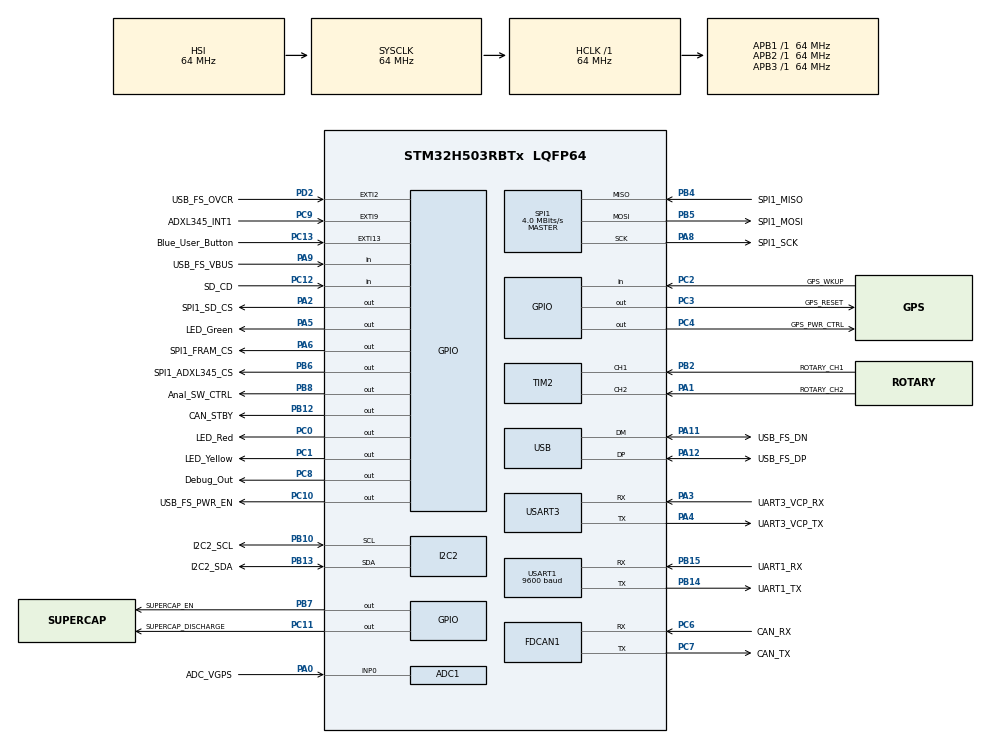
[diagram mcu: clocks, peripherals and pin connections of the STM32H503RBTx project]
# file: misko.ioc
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ADC1.Channel-1\#ChannelRegularConversion=ADC_CHANNEL_0
ADC1.Channel-2\#ChannelRegularConversion=ADC_CHANNEL_VBAT
ADC1.Channel-3\#ChannelRegularConversion=ADC_CHANNEL_TEMPSENSOR
ADC1.Channel-4\#ChannelRegularConversion=ADC_CHANNEL_VREFINT
ADC1.DMAContinuousRequests=ENABLE
ADC1.EnableAnalogWatchDog2=false
ADC1.ExternalTrigConv=ADC_EXTERNALTRIG_T1_TRGO
ADC1.MonitoredBy-1\#ChannelRegularConversion=__NULL
ADC1.MonitoredBy-2\#ChannelRegularConversion=__NULL
ADC1.MonitoredBy-3\#ChannelRegularConversion=__NULL
ADC1.MonitoredBy-4\#ChannelRegularConversion=__NULL
ADC1.NbrOfConversion=4
ADC1.NbrOfConversionFlag=1
ADC1.Offset-1\#ChannelRegularConversion=0
ADC1.Offset-2\#ChannelRegularConversion=0
ADC1.Offset-3\#ChannelRegularConversion=0
ADC1.Offset-4\#ChannelRegularConversion=0
ADC1.OffsetNumber-1\#ChannelRegularConversion=ADC_OFFSET_NONE
ADC1.OffsetNumber-2\#ChannelRegularConversion=ADC_OFFSET_NONE
ADC1.OffsetNumber-3\#ChannelRegularConversion=ADC_OFFSET_NONE
ADC1.OffsetNumber-4\#ChannelRegularConversion=ADC_OFFSET_NONE
ADC1.Overrun=ADC_OVR_DATA_OVERWRITTEN
ADC1.Rank-1\#ChannelRegularConversion=1
ADC1.Rank-2\#ChannelRegularConversion=2
ADC1.Rank-3\#ChannelRegularConversion=3
ADC1.Rank-4\#ChannelRegularConversion=4
ADC1.Resolution=ADC_RESOLUTION_12B
ADC1.SamplingTime-1\#ChannelRegularConversion=ADC_SAMPLETIME_640CYCLES_5
ADC1.SamplingTime-2\#ChannelRegularConversion=ADC_SAMPLETIME_640CYCLES_5
ADC1.SamplingTime-3\#ChannelRegularConversion=ADC_SAMPLETIME_640CYCLES_5
ADC1.SamplingTime-4\#ChannelRegularConversion=ADC_SAMPLETIME_640CYCLES_5
ADC1.master=1
BOOTPATH.BootPathName=LEGACY
BOOTPATH.UserSelectedBootPath=LEGACY
CORTEX_M33_NS.AccessPermission-Cortex_Memory_Protection_Unit_Region0_Settings=MPU_REGION_ALL_RO
CORTEX_M33_NS.BaseAddress-Cortex_Memory_Protection_Unit_Region0_Settings=0x08FFF810
CORTEX_M33_NS.DisableExec-Cortex_Memory_Protection_Unit_Region0_Settings=MPU_INSTRUCTION_ACCESS_DISABLE
CORTEX_M33_NS.Enable-Cortex_Memory_Protection_Unit_Region0_Settings=MPU_REGION_ENABLE
CORTEX_M33_NS.LimitAddress-Cortex_Memory_Protection_Unit_Region0_Settings=0x08FFF819
CORTEX_M33_NS.MPU_Control=MPU_HFNMI_PRIVDEF
FDCAN1.CalculateBaudRateNominal=166666
FDCAN1.CalculateTimeBitNominal=6000
FDCAN1.CalculateTimeQuantumNominal=2000.0
FDCAN1.ClockDivider=FDCAN_CLOCK_DIV1
GPDMA1.CIRCULARMODE_GPDMACH1=ENABLE
GPDMA1.CIRCULARMODE_GPDMACH3=ENABLE
GPDMA1.CIRCULARMODE_GPDMACH5=ENABLE
GPDMA1.DESTDATAWIDTH_GPDMACH5=DMA_DEST_DATAWIDTH_WORD
GPDMA1.DESTINC_GPDMACH1=DMA_DINC_INCREMENTED
GPDMA1.DESTINC_GPDMACH3=DMA_DINC_INCREMENTED
GPDMA1.DESTINC_GPDMACH5=DMA_DINC_INCREMENTED
GPDMA1.DIRECTION_GPDMACH0=DMA_MEMORY_TO_PERIPH
GPDMA1.IPHANDLE_GPDMACH0-SIMPLEREQUEST_GPDMACH0=__NULL
GPDMA1.IPHANDLE_GPDMACH1-SIMPLEREQUEST_GPDMACH1=__NULL
GPDMA1.IPHANDLE_GPDMACH3-SIMPLEREQUEST_GPDMACH3=__NULL
GPDMA1.IPHANDLE_GPDMACH5-SIMPLEREQUEST_GPDMACH5=__NULL
GPDMA1.LINKALLOCATEDPORT_CIRCULAR_GPDMACH1=DMA_LINK_ALLOCATED_PORT1
GPDMA1.LINKALLOCATEDPORT_GPDMACH7=DMA_LINK_ALLOCATED_PORT1
GPDMA1.PRIORITY_LL_GPDMACH6=DMA_LOW_PRIORITY_HIGH_WEIGHT
GPDMA1.PRIORITY_LL_GPDMACH7=DMA_LOW_PRIORITY_HIGH_WEIGHT
GPDMA1.RECAP_GPDMACH0=USART3_TX
GPDMA1.RECAP_GPDMACH1=USART3_RX
GPDMA1.RECAP_GPDMACH3=USART1_RX
GPDMA1.RECAP_GPDMACH5=ADC1
GPDMA1.REQUEST_GPDMACH0=GPDMA1_REQUEST_USART3_TX
GPDMA1.REQUEST_GPDMACH1=GPDMA1_REQUEST_USART3_RX
GPDMA1.REQUEST_GPDMACH3=GPDMA1_REQUEST_USART1_RX
GPDMA1.REQUEST_GPDMACH5=GPDMA1_REQUEST_ADC1
GPDMA1.SRCDATAWIDTH_GPDMACH5=DMA_SRC_DATAWIDTH_WORD
GPDMA1.SRCINC_GPDMACH0=DMA_SINC_INCREMENTED
GPDMA1.TRANSFERALLOCATEDPORTDEST_GPDMACH1=DMA_DEST_ALLOCATED_PORT1
GPDMA1.TRANSFERALLOCATEDPORTSRC_GPDMACH1=DMA_SRC_ALLOCATED_PORT1
GPDMA1.TRIGGERPOLARITY_GPDMACH5=DMA_TRIG_POLARITY_MASKED
GPDMA2.DESTINC_GPDMACH1=DMA_DINC_INCREMENTED
GPDMA2.IPHANDLE_GPDMACH0-SIMPLEREQUEST_GPDMACH0=__NULL
GPDMA2.IPHANDLE_GPDMACH1-SIMPLEREQUEST_GPDMACH1=__NULL
GPDMA2.REQUEST_GPDMACH0=GPDMA2_REQUEST_I2C2_TX
GPDMA2.REQUEST_GPDMACH1=GPDMA2_REQUEST_I2C2_RX
GPDMA2.SRCINC_GPDMACH0=DMA_SINC_INCREMENTED
I2C2.Timing=0x10707DBC
Linkedlist.MDMA_Channel0.GP_SW.0.BlkHWRequest=DMA_BREQ_SINGLE_BURST
Linkedlist.MDMA_Channel0.GP_SW.0.DataHandling=NONE
Linkedlist.MDMA_Channel0.GP_SW.0.DataSize=0
Linkedlist.MDMA_Channel0.GP_SW.0.DestBurstLength=1
Linkedlist.MDMA_Channel0.GP_SW.0.DestDataWidth=DMA_DEST_DATAWIDTH_BYTE
Linkedlist.MDMA_Channel0.GP_SW.0.DestInc=DMA_DINC_FIXED
Linkedlist.MDMA_Channel0.GP_SW.0.Direction=DMA_MEMORY_TO_PERIPH
Linkedlist.MDMA_Channel0.GP_SW.0.DstAddress=0
Linkedlist.MDMA_Channel0.GP_SW.0.Instance=MDMA_Channel0
Linkedlist.MDMA_Channel0.GP_SW.0.LL_MASTERDMA=GPDMA1
Linkedlist.MDMA_Channel0.GP_SW.0.LL_NAME=Queue_tx
Linkedlist.MDMA_Channel0.GP_SW.0.LL_TYPE=LINEAR
Linkedlist.MDMA_Channel0.GP_SW.0.Mode=DMA_NORMAL
Linkedlist.MDMA_Channel0.GP_SW.0.NODE_NAME=Node_tx
Linkedlist.MDMA_Channel0.GP_SW.0.Requestforcodegen=GPDMA1_REQUEST_SPI1_TX
Linkedlist.MDMA_Channel0.GP_SW.0.SrcAddress=0
Linkedlist.MDMA_Channel0.GP_SW.0.SrcBurstLength=1
Linkedlist.MDMA_Channel0.GP_SW.0.SrcDataWidth=DMA_SRC_DATAWIDTH_BYTE
Linkedlist.MDMA_Channel0.GP_SW.0.SrcInc=DMA_SINC_INCREMENTED
Linkedlist.MDMA_Channel0.GP_SW.0.TransferAllocatedPortSrc=DMA_SRC_ALLOCATED_PORT1
Linkedlist.MDMA_Channel0.GP_SW.0.TransferEventMode=DMA_TCEM_BLOCK_TRANSFER
Linkedlist.MDMA_Channel0.GP_SW.0.TriggerPolarity=DMA_TRIG_POLARITY_MASKED
Linkedlist.MDMA_Channel0.Request0=GP_SW
Linkedlist.MDMA_Channel0.RequestsNb=1
Linkedlist.MDMA_Channel1.GP_SW.0.BlkHWRequest=DMA_BREQ_SINGLE_BURST
Linkedlist.MDMA_Channel1.GP_SW.0.DataHandling=NONE
Linkedlist.MDMA_Channel1.GP_SW.0.DataSize=0
Linkedlist.MDMA_Channel1.GP_SW.0.DestBurstLength=1
Linkedlist.MDMA_Channel1.GP_SW.0.DestDataWidth=DMA_DEST_DATAWIDTH_BYTE
Linkedlist.MDMA_Channel1.GP_SW.0.DestInc=DMA_DINC_INCREMENTED
Linkedlist.MDMA_Channel1.GP_SW.0.Direction=DMA_PERIPH_TO_MEMORY
Linkedlist.MDMA_Channel1.GP_SW.0.DstAddress=0
Linkedlist.MDMA_Channel1.GP_SW.0.Instance=MDMA_Channel1
Linkedlist.MDMA_Channel1.GP_SW.0.LL_MASTERDMA=GPDMA1
Linkedlist.MDMA_Channel1.GP_SW.0.LL_NAME=Queue_rx
Linkedlist.MDMA_Channel1.GP_SW.0.LL_TYPE=LINEAR
Linkedlist.MDMA_Channel1.GP_SW.0.Mode=DMA_NORMAL
Linkedlist.MDMA_Channel1.GP_SW.0.NODE_NAME=Node_rx
Linkedlist.MDMA_Channel1.GP_SW.0.Requestforcodegen=GPDMA1_REQUEST_SPI1_RX
Linkedlist.MDMA_Channel1.GP_SW.0.SrcAddress=0
Linkedlist.MDMA_Channel1.GP_SW.0.SrcBurstLength=1
Linkedlist.MDMA_Channel1.GP_SW.0.SrcDataWidth=DMA_SRC_DATAWIDTH_BYTE
Linkedlist.MDMA_Channel1.GP_SW.0.SrcInc=DMA_SINC_FIXED
Linkedlist.MDMA_Channel1.GP_SW.0.TransferAllocatedPortSrc=DMA_SRC_ALLOCATED_PORT0
Linkedlist.MDMA_Channel1.GP_SW.0.TransferEventMode=DMA_TCEM_BLOCK_TRANSFER
Linkedlist.MDMA_Channel1.GP_SW.0.TriggerPolarity=DMA_TRIG_POLARITY_MASKED
Linkedlist.MDMA_Channel1.Request0=GP_SW
Linkedlist.MDMA_Channel1.RequestsNb=1
Linkedlist.RequestSet0=MDMA_Channel0
Linkedlist.RequestSet1=MDMA_Channel1
Linkedlist.RequestSetsNb=2
Mcu.Family=STM32H5
Mcu.Name=STM32H503RBTx
Mcu.Package=LQFP64
NVIC.ADC1_IRQn=true\:0\:0\:false\:false\:true\:true\:true\:true
NVIC.EXTI13_IRQn=true\:4\:0\:true\:false\:true\:true\:true\:true
NVIC.EXTI2_IRQn=true\:0\:0\:false\:false\:true\:true\:true\:true
NVIC.EXTI9_IRQn=true\:1\:0\:true\:false\:true\:true\:true\:true
NVIC.FDCAN1_IT0_IRQn=true\:0\:0\:false\:false\:true\:true\:true\:true
NVIC.FDCAN1_IT1_IRQn=true\:0\:0\:false\:false\:true\:true\:true\:true
NVIC.GPDMA1_Channel0_IRQn=true\:0\:0\:false\:false\:true\:true\:true\:true
NVIC.GPDMA1_Channel1_IRQn=true\:0\:0\:false\:false\:true\:true\:true\:true
NVIC.GPDMA1_Channel3_IRQn=true\:0\:0\:true\:false\:true\:false\:true\:true
NVIC.GPDMA1_Channel5_IRQn=true\:0\:0\:false\:false\:true\:false\:true\:true
NVIC.GPDMA1_Channel6_IRQn=true\:0\:0\:false\:false\:true\:true\:true\:true
NVIC.GPDMA1_Channel7_IRQn=true\:0\:0\:false\:false\:true\:true\:true\:true
NVIC.GPDMA2_Channel0_IRQn=true\:0\:0\:false\:false\:true\:false\:true\:true
NVIC.GPDMA2_Channel1_IRQn=true\:0\:0\:false\:false\:true\:false\:true\:true
NVIC.PriorityGroup=NVIC_PRIORITYGROUP_3
NVIC.SPI1_IRQn=true\:0\:0\:false\:false\:true\:true\:true\:true
NVIC.TIM1_CC_IRQn=true\:0\:0\:false\:false\:true\:true\:true\:true
NVIC.TIM2_IRQn=true\:0\:0\:false\:false\:true\:true\:true\:true
NVIC.USART1_IRQn=true\:2\:0\:true\:false\:true\:true\:true\:true
NVIC.USART3_IRQn=true\:3\:0\:true\:false\:true\:true\:true\:true
PA0.GPIO_Label=ADC_VGPS
PA0.Signal=ADCx_INP0
PA1.GPIO_Label=ROTARY_CH2
PA1.Signal=S_TIM2_CH2
PA11.GPIO_Label=USB_FS_DN
PA11.Mode=Device
PA11.Signal=USB_DM
PA12.GPIO_Label=USB_FS_DP
PA12.Mode=Device
PA12.Signal=USB_DP
PA13(JTMS/SWDIO).GPIO_Label=SWDIO
PA13(JTMS/SWDIO).Mode=JTAG_4_pins
PA13(JTMS/SWDIO).Signal=DEBUG_JTMS-SWDIO
PA14(JTCK/SWCLK).GPIO_Label=SWCLK
PA14(JTCK/SWCLK).Mode=JTAG_4_pins
PA14(JTCK/SWCLK).Signal=DEBUG_JTCK-SWCLK
PA15(JTDI).GPIO_Label=JTDI
PA15(JTDI).Mode=JTAG_4_pins
PA15(JTDI).Signal=DEBUG_JTDI
PA2.GPIO_Label=SPI1_SD_CS
PA2.GPIO_PuPd=GPIO_PULLUP
PA2.PinState=GPIO_PIN_SET
PA2.Signal=GPIO_Output
PA3.GPIO_Label=UART3_VCP_RX
PA3.GPIO_PuPd=GPIO_PULLUP
PA3.Mode=Asynchronous
PA3.Signal=USART3_RX
PA4.GPIO_Label=UART3_VCP_TX
PA4.GPIO_PuPd=GPIO_PULLUP
PA4.Mode=Asynchronous
PA4.Signal=USART3_TX
PA5.GPIO_Label=LED_Green
PA5.PinState=GPIO_PIN_RESET
PA5.Signal=GPIO_Output
PA6.GPIO_Label=SPI1_FRAM_CS
PA6.GPIO_PuPd=GPIO_PULLUP
PA6.PinState=GPIO_PIN_SET
PA6.Signal=GPIO_Output
PA8.GPIO_Label=SPI1_SCK
PA8.GPIO_PuPd=GPIO_PULLUP
PA8.Mode=Full_Duplex_Master
PA8.Signal=SPI1_SCK
PA9.GPIO_Label=USB_FS_VBUS
PA9.Signal=GPIO_Input
PB10.GPIO_Label=I2C2_SCL
PB10.GPIO_Pu=GPIO_PULLUP
PB10.Mode=I2C
PB10.Signal=I2C2_SCL
PB12.GPIO_Label=CAN_STBY
PB12.Signal=GPIO_Output
PB13.GPIO_Label=I2C2_SDA
PB13.GPIO_Pu=GPIO_PULLUP
PB13.Mode=I2C
PB13.Signal=I2C2_SDA
PB14.GPIO_Label=UART1_TX
PB14.GPIO_PuPd=GPIO_PULLUP
PB14.Mode=Asynchronous
PB14.Signal=USART1_TX
PB15.GPIO_Label=UART1_RX
PB15.GPIO_PuPd=GPIO_PULLUP
PB15.Mode=Asynchronous
PB15.Signal=USART1_RX
PB2.GPIO_Label=ROTARY_CH1
PB2.Signal=S_TIM2_CH1
PB3(JTDO/TRACESWO).GPIO_Label=SWO
PB3(JTDO/TRACESWO).Mode=JTAG_4_pins
PB3(JTDO/TRACESWO).Signal=DEBUG_JTDO-SWO
PB4(NJTRST).GPIO_Label=SPI1_MISO
PB4(NJTRST).GPIO_PuPd=GPIO_PULLUP
PB4(NJTRST).Mode=Full_Duplex_Master
PB4(NJTRST).Signal=SPI1_MISO
PB5.GPIO_Label=SPI1_MOSI
PB5.GPIO_PuPd=GPIO_PULLUP
PB5.Mode=Full_Duplex_Master
PB5.Signal=SPI1_MOSI
PB6.GPIO_Label=SPI1_ADXL345_CS
PB6.GPIO_PuPd=GPIO_PULLUP
PB6.PinState=GPIO_PIN_SET
PB6.Signal=GPIO_Output
PB7.GPIO_Label=SUPERCAP_EN
PB7.GPIO_PuPd=GPIO_PULLDOWN
PB7.Signal=GPIO_Output
PB8.GPIO_Label=Anal_SW_CTRL
PB8.GPIO_PuPd=GPIO_PULLUP
PB8.PinState=GPIO_PIN_SET
PB8.Signal=GPIO_Output
PC0.GPIO_Label=LED_Red
PC0.PinState=GPIO_PIN_RESET
PC0.Signal=GPIO_Output
PC1.GPIO_Label=LED_Yellow
PC1.GPIO_PuPd=GPIO_NOPULL
PC1.PinState=GPIO_PIN_RESET
PC1.Signal=GPIO_Output
PC10.GPIO_Label=USB_FS_PWR_EN
PC10.Signal=GPIO_Output
PC11.GPIO_Label=SUPERCAP_DISCHARGE
PC11.GPIO_PuPd=GPIO_PULLDOWN
PC11.PinState=GPIO_PIN_RESET
PC11.Signal=GPIO_Output
PC12.GPIO_Label=SD_CD
PC12.GPIO_PuPd=GPIO_PULLUP
PC12.Signal=GPIO_Input
PC13.GPIO_Label=Blue_User_Button
PC13.Signal=GPXTI13
PC14-OSC32_IN(OSC32_IN).Mode=LSE-External-Oscillator
PC14-OSC32_IN(OSC32_IN).Signal=RCC_OSC32_IN
PC15-OSC32_OUT(OSC32_OUT).Mode=LSE-External-Oscillator
PC15-OSC32_OUT(OSC32_OUT).Signal=RCC_OSC32_OUT
PC2.GPIO_Label=GPS_WKUP
PC2.GPIO_PuPd=GPIO_PULLDOWN
PC2.Signal=GPIO_Input
PC3.GPIO_Label=GPS_RESET
PC3.GPIO_PuPd=GPIO_PULLUP
PC3.PinState=GPIO_PIN_SET
PC3.Signal=GPIO_Output
PC4.GPIO_Label=GPS_PWR_CTRL
PC4.GPIO_PuPd=GPIO_PULLDOWN
PC4.Signal=GPIO_Output
PC6.GPIO_Label=CAN_RX
PC6.Mode=FDCAN_Activate
PC6.Signal=FDCAN1_RX
PC7.GPIO_Label=CAN_TX
PC7.Mode=FDCAN_Activate
PC7.Signal=FDCAN1_TX
PC8.GPIO_Label=Debug_Out
PC8.GPIO_Speed=GPIO_SPEED_FREQ_VERY_HIGH
PC8.Signal=GPIO_Output
PC9.GPIO_Label=ADXL345_INT1
PC9.GPIO_ModeDefaultEXTI=GPIO_MODE_IT_RISING
PC9.Signal=GPXTI9
PD2.GPIO_Label=USB_FS_OVCR
PD2.Signal=GPXTI2
PH0-OSC_IN(PH0).Mode=HSE-External-Oscillator
PH0-OSC_IN(PH0).Signal=RCC_OSC_IN
PH1-OSC_OUT(PH1).Mode=HSE-External-Oscillator
PH1-OSC_OUT(PH1).Signal=RCC_OSC_OUT
ProjectManager.HeapSize=0x200
ProjectManager.StackSize=0x400
ProjectManager.TargetToolchain=STM32CubeIDE
RCC.ADCCLockSelection=RCC_ADCDACCLKSOURCE_PLL2R
RCC.ADCFreq_Value=8000000
RCC.AHBFreq_Value=64000000
RCC.APB1Freq_Value=64000000
RCC.APB1TimFreq_Value=64000000
RCC.APB2Freq_Value=64000000
RCC.APB2TimFreq_Value=64000000
RCC.APB3Freq_Value=64000000
RCC.CSI_VALUE=4000000
RCC.CortexFreq_Value=64000000
RCC.DATA_CACHE_ENABLE=1
RCC.EPOD_VALUE=64000000
RCC.FDCANClockSelection=RCC_FDCANCLKSOURCE_PLL2Q
RCC.HCLKFreq_Value=64000000
RCC.HSE_VALUE=24000000
RCC.HSI48_VALUE=48000000
RCC.HSIDiv=RCC_HSI_DIV1
RCC.HSI_VALUE=64000000
RCC.INSTRUCTION_CACHE_ENABLE=1
RCC.LPUART1CLockSelection=RCC_LPUART1CLKSOURCE_HSI
RCC.LSIRC_VALUE=32000
RCC.MSICalibrationValue=0
RCC.PLL2M=4
RCC.PLL2N=8
RCC.PLL2P=16
RCC.PLL2Q=16
RCC.PLL2R=16
RCC.PLL2Source=RCC_PLL2_SOURCE_HSI
RCC.PLLFRACN=0
RCC.PLLM=4
RCC.PLLN=8
RCC.PLLSourceVirtual=RCC_PLL1_SOURCE_HSI
RCC.PREFETCH_ENABLE=0
RCC.SPI1CLockSelection=RCC_SPI1CLKSOURCE_PLL2P
RCC.SYSCLKFreq_VALUE=64000000
RCC.USART1CLockSelection=RCC_USART1CLKSOURCE_HSI
RCC.USART3CLockSelection=RCC_USART3CLKSOURCE_HSI
RCC.USBFreq_Value=48000000
RCC.VCOOutputFreq_Value=128000000
RTC.Date=5
RTC.Format=RTC_FORMAT_BIN
RTC.Hours=23
RTC.Minutes=59
RTC.WeekDay=RTC_WEEKDAY_SATURDAY
RTC.Year=80
SH.ADCx_INP0.0=ADC1_INP0,IN0-Single-Ended
SH.S_TIM2_CH1.0=TIM2_CH1,Encoder_Interface
SH.S_TIM2_CH2.0=TIM2_CH2,Encoder_Interface
SPI1.BaudRatePrescaler=SPI_BAUDRATEPRESCALER_2
SPI1.CLKPhase=SPI_PHASE_2EDGE
SPI1.CLKPolarity=SPI_POLARITY_HIGH
SPI1.CalculateBaudRate=4.0 MBits/s
SPI1.DataSize=SPI_DATASIZE_8BIT
SPI1.Direction=SPI_DIRECTION_2LINES
SPI1.MasterKeepIOState=SPI_MASTER_KEEP_IO_STATE_DISABLE
SPI1.Mode=SPI_MODE_MASTER
SPI1.NSSPolarity=SPI_NSS_POLARITY_LOW
SPI1.VirtualType=VM_MASTER
TIM1.PeriodNoDither=6260
TIM1.Prescaler=639
TIM1.TIM_MasterOutputTrigger=TIM_TRGO_UPDATE
USART1.AutoBaudRateEnableParam=UART_ADVFEATURE_AUTOBAUDRATE_DISABLE
USART1.BaudRate=9600
USART1.VirtualMode=VM_ASYNC
USART1.VirtualMode-Asynchronous=VM_ASYNC
USART3.VirtualMode=VM_ASYNC
USART3.VirtualMode-Asynchronous=VM_ASYNC
USB.VirtualMode=Device_Only
VP_ADC1_TempSens_Input.Mode=IN-TempSens
VP_ADC1_Vbat_Input.Mode=IN-Vbat
VP_ADC1_Vref_Input.Mode=IN-Vrefint
VP_BOOTPATH_VS_BOOTPATH.Mode=BP_Activate
VP_CORTEX_M33_NS_VS_Hclk.Mode=Hclk_Mode
VP_GPDMA1_VS_GPDMACH0.Mode=SIMPLEREQUEST_GPDMACH0
VP_GPDMA1_VS_GPDMACH1.Mode=SIMPLEREQUEST_GPDMACH1
VP_GPDMA1_VS_GPDMACH3.Mode=SIMPLEREQUEST_GPDMACH3
VP_GPDMA1_VS_GPDMACH5.Mode=SIMPLEREQUEST_GPDMACH5
VP_GPDMA1_VS_GPDMACH6.Mode=LINKEDLIST_GPDMACH6
VP_GPDMA1_VS_GPDMACH7.Mode=LINKEDLIST_GPDMACH7
VP_GPDMA2_VS_GPDMACH0.Mode=SIMPLEREQUEST_GPDMACH0
VP_GPDMA2_VS_GPDMACH1.Mode=SIMPLEREQUEST_GPDMACH1
VP_ICACHE_VS_ICACHE.Mode=DefaultMode
VP_MEMORYMAP_VS_MEMORYMAP.Mode=CurAppReg
VP_PWR_VS_DBSignals.Mode=DisableDeadBatterySignals
VP_PWR_VS_LPOM.Mode=PowerOptimisation
VP_PWR_VS_SECSignals.Mode=Security/Privilege
VP_RTC_VS_RTC_Activate.Mode=RTC_Enabled
VP_RTC_VS_RTC_Calendar.Mode=RTC_Calendar
VP_TIM1_VS_ClockSourceINT.Mode=Internal
board=NUCLEO-H503RB

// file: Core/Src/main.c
/* USER CODE BEGIN Header */
/**
 ******************************************************************************
 * @file           : main.c
 * @brief          : Main program body
 ******************************************************************************
 * @attention
 *
 * Copyright (c) 2024 STMicroelectronics.
 * All rights reserved.
 *
 * This software is licensed under terms that can be found in the LICENSE file
 * in the root directory of this software component.
 * If no LICENSE file comes with this software, it is provided AS-IS.
 *
 ******************************************************************************
 */
/* USER CODE END Header */
#include "main.h"

/* USER CODE BEGIN Includes */
#include "lwrb/lwrb.h"	// LightWeight Ringbuffer

#if USE_ADXL345
#include "adxl345/adxl345.h"
#endif
#if USE_FM25W256
#include "fm25w256/fm25w256.h"
#endif
#if USE_SD
#include "sd/sd.h"
#endif
#if USE_ORG1510MK4
#include "org1510mk4/org1510mk4.h"
#endif
#if USE_TIMEHELPER
#include "timehelper/timehelper.h"
#endif
#if USE_LOGGER
#include "logger/logger.h"
#endif
/* USER CODE END Includes */

/* USER CODE BEGIN PD */
#define DEBUG_SYS_RX_RB_FREE 1 // data member indicating LwRB free space

#define UART3_SYS_RX_DMA_BUFFER_LEN 32	// circular DMA RX buffer length for incoming GPS UART DMA data
#define UART3_SYS_RX_RINGBUFFER_LEN 256	// ringbuffer size
/* USER CODE END PD */

ADC_HandleTypeDef hadc1;
DMA_NodeTypeDef Node_GPDMA1_Channel5;
DMA_QListTypeDef List_GPDMA1_Channel5;
DMA_HandleTypeDef handle_GPDMA1_Channel5;

FDCAN_HandleTypeDef hfdcan1;

DMA_HandleTypeDef handle_GPDMA1_Channel7;
DMA_HandleTypeDef handle_GPDMA1_Channel6;

I2C_HandleTypeDef hi2c2;
DMA_HandleTypeDef handle_GPDMA2_Channel1;
DMA_HandleTypeDef handle_GPDMA2_Channel0;

RTC_HandleTypeDef hrtc;

SPI_HandleTypeDef hspi1;

TIM_HandleTypeDef htim1;
TIM_HandleTypeDef htim2;

UART_HandleTypeDef huart1;
UART_HandleTypeDef huart3;
DMA_NodeTypeDef Node_GPDMA1_Channel3;
DMA_QListTypeDef List_GPDMA1_Channel3;
DMA_HandleTypeDef handle_GPDMA1_Channel3;
DMA_NodeTypeDef Node_GPDMA1_Channel1;
DMA_QListTypeDef List_GPDMA1_Channel1;
DMA_HandleTypeDef handle_GPDMA1_Channel1;
DMA_HandleTypeDef handle_GPDMA1_Channel0;

PCD_HandleTypeDef hpcd_USB_DRD_FS;

/* USER CODE BEGIN PV */
static lwrb_t uart3_sys_rx_rb;  // 2nd circular buffer for data processing
static uint8_t uart3_sys_rx_rb_buffer[UART3_SYS_RX_RINGBUFFER_LEN];  //
static uint8_t uart3_sys_rx_dma_buffer[UART3_SYS_RX_DMA_BUFFER_LEN];  //

static uint8_t VCPTxBuffer[82] = "\rnucleo-h503rb start\r\n";

volatile uint32_t __adc_dma_buffer[ADC_CHANNELS] =  // store for ADC readout
	{0};
volatile uint32_t __adc_results[ADC_CHANNELS] =  // store ADC average data
	{0};
double _VddaConversionConstant;  // constant values pre-computed in main()

static uint8_t SYS_out[82] = "\0";  // output box for GPS UART's DMA

#if DEBUG_LWRB_FREE
uint16_t uart3_lwrb_free;  // ringbuffer free memory
uint32_t uart3_char_written;	// characters written
lwrb_sz_t uart3_ovrflowlen;  // amount of data written in overflow mode
lwrb_sz_t uart3_linearlen;  // amount of data written in linear mode
#endif
logger_t *mj8x8_log;	// logger object for mj8x8 data
logger_t *gps_log;	// logger object for GPS data
/* USER CODE END PV */

void SystemClock_Config(void);
void PeriphCommonClock_Config(void);
static void MPU_Config(void);
static void MX_GPIO_Init(void);
static void MX_GPDMA1_Init(void);
static void MX_GPDMA2_Init(void);
static void MX_ICACHE_Init(void);
static void MX_USB_PCD_Init(void);
static void MX_USART3_UART_Init(void);
static void MX_TIM1_Init(void);
static void MX_SPI1_Init(void);
static void MX_FDCAN1_Init(void);
static void MX_ADC1_Init(void);
static void MX_USART1_UART_Init(void);
static void MX_I2C2_Init(void);
static void MX_TIM2_Init(void);
static void MX_RTC_Init(void);

/* USER CODE BEGIN 0 */
static void load_into_ring_buffer(lwrb_t *rb, const uint16_t high_pos)
{
	static uint16_t low_pos;

	// safeguard against an RX event interrupt where no new data has come in
	if(high_pos == low_pos)  // no new data
		return;

	// 1st buffering - load into ringbuffer
	if(high_pos > low_pos)  // linear region
		// read in a linear fashion from DMA rcpt. buffer from beginning to end of new data
		lwrb_write(rb, &uart3_sys_rx_dma_buffer[low_pos], high_pos - low_pos);  // (high_pos - low_pos) is length of new data
	else	// overflow region
		{
			// read new data from current position until end of DMA rcpt. buffer
			lwrb_write(&uart3_sys_rx_rb, &uart3_sys_rx_dma_buffer[low_pos], UART3_SYS_RX_DMA_BUFFER_LEN - low_pos);

			// then, if there is more after the rollover
			if(high_pos > 0)
				// read from beginning of circular DMA buffer until the end position of new data
				lwrb_write(rb, &uart3_sys_rx_dma_buffer[0], high_pos);
		}

	low_pos = high_pos;  // save position until data has been read

#if DEBUG_SYS_RB_FREE
	uart3_lwrb_free = (uint16_t) lwrb_get_free(&uart3_sys_rx_rb);  // have free memory value visible

	if(uart3_lwrb_free == 0)  // LwRB memory used up: hang here
		Error_Handler();
#endif
}
/* USER CODE END 0 */

int main(void)
{

	/* MCU Configuration--------------------------------------------------------*/

	/* MPU Configuration--------------------------------------------------------*/
	MPU_Config();

	/* Reset of all peripherals, Initializes the Flash interface and the Systick. */
	HAL_Init();

	/* Configure the system clock */
	SystemClock_Config();

	/* Configure the peripherals common clocks */
	PeriphCommonClock_Config();

	/* Initialize all configured peripherals */
	MX_GPIO_Init();
	MX_GPDMA1_Init();
	MX_GPDMA2_Init();
	MX_ICACHE_Init();
	MX_USB_PCD_Init();
	MX_USART3_UART_Init();
	MX_TIM1_Init();
	MX_SPI1_Init();
	MX_FDCAN1_Init();
	MX_ADC1_Init();
	MX_USART1_UART_Init();
	MX_I2C2_Init();
	MX_TIM2_Init();
	MX_RTC_Init();
	/* USER CODE BEGIN 2 */

	// 125ms time base
	if(HAL_TIM_OC_Start_IT(&htim1, TIM_CHANNEL_1) != HAL_OK)
		Error_Handler();

	// start ADC
	_VddaConversionConstant = (VREFINT_CAL_VREF * *VREFINT_CAL_ADDR) / 4095.0;  // 1203.95604
	HAL_ADC_Start_DMA(&hadc1, (uint32_t*) __adc_dma_buffer, ADC_CHANNELS);

	// SPI DMA stuff
	MX_Queue_tx_Config();
	HAL_DMAEx_List_LinkQ(&handle_GPDMA1_Channel7, &Queue_tx);
	__HAL_LINKDMA(&hspi1, hdmatx, handle_GPDMA1_Channel7);
	MX_Queue_rx_Config();
	HAL_DMAEx_List_LinkQ(&handle_GPDMA1_Channel6, &Queue_rx);
	__HAL_LINKDMA(&hspi1, hdmarx, handle_GPDMA1_Channel6);

	// transmit hello world over VCP
	if(HAL_UART_Transmit_DMA(&huart3, (uint8_t*) VCPTxBuffer, (uint16_t) strlen((const char*) VCPTxBuffer)) != HAL_OK)
		Error_Handler();

	// initialize the ringbuffer and ...
	lwrb_init(&uart3_sys_rx_rb, uart3_sys_rx_rb_buffer, sizeof(uart3_sys_rx_rb_buffer));

	// ... start to receive whatever from VCP
	if(HAL_OK != HAL_UARTEx_ReceiveToIdle_DMA(&huart3, uart3_sys_rx_dma_buffer, UART3_SYS_RX_DMA_BUFFER_LEN))  // start reception)
		Error_Handler();

	// start peripheral devices
#if USE_ADXL345
	adxl345_ctor(&hspi1, SPI1_ADXL345_CS_GPIO_Port, SPI1_ADXL345_CS_Pin);  // initialize accelerometer object
#endif
#if USE_FM25W256
	fm25w256_ctor(&hspi1, SPI1_FRAM_CS_GPIO_Port, SPI1_FRAM_CS_Pin);  //initialize FeRAM object
#endif
#if USE_SD
	sd_ctor(&hspi1, SPI1_SD_CS_GPIO_Port, SPI1_SD_CS_Pin, SD_CD_GPIO_Port, SD_CD_Pin);  // initialize SD Card object
#endif
#if USE_ORG1510MK4
	org1510mk4_ctor(&huart1, &huart3);  // initialise the GPS module object
#endif
#if USE_TIMEHELPER
	timehelper_ctor(ORG1510MK4, &hrtc);  // initialize TimeHelper object
#endif
#if USE_LOGGER
	mj8x8_log = logger_ctor();
	gps_log = logger_ctor();
#endif
	/* USER CODE END 2 */

	/* Infinite loop */
	/* USER CODE BEGIN WHILE */
	while(1)
		{
#if PARSE_GSV
			ORG1510MK4->AlmEphQuery();	// asynchronous flag_alm_eph_query for SV almanac & ephemeris
#endif
			TimeHelper->TimeHelper(ORG1510MK4->FlagTimeAccurate);  // deal with time...
#if PARSE_PMTK
			TimeHelper->LocationHelper(0);  // seed the last known location
#endif
			/* USER CODE END WHILE */

		}
}

void SystemClock_Config(void)
{
	RCC_OscInitTypeDef RCC_OscInitStruct =
		{0};
	RCC_ClkInitTypeDef RCC_ClkInitStruct =
		{0};

	/** Configure the main internal regulator output voltage
	 */
	__HAL_PWR_VOLTAGESCALING_CONFIG(PWR_REGULATOR_VOLTAGE_SCALE3);

	while(!__HAL_PWR_GET_FLAG(PWR_FLAG_VOSRDY))
		{
		}

	/** Initializes the RCC Oscillators according to the specified parameters
	 * in the RCC_OscInitTypeDef structure.
	 */
	RCC_OscInitStruct.OscillatorType = RCC_OSCILLATORTYPE_HSI48 | RCC_OSCILLATORTYPE_HSI | RCC_OSCILLATORTYPE_LSI;
	RCC_OscInitStruct.HSIState = RCC_HSI_ON;
	RCC_OscInitStruct.HSIDiv = RCC_HSI_DIV1;
	RCC_OscInitStruct.HSICalibrationValue = RCC_HSICALIBRATION_DEFAULT;
	RCC_OscInitStruct.LSIState = RCC_LSI_ON;
	RCC_OscInitStruct.HSI48State = RCC_HSI48_ON;
	RCC_OscInitStruct.PLL.PLLState = RCC_PLL_NONE;
	if(HAL_RCC_OscConfig(&RCC_OscInitStruct) != HAL_OK)
		{
			Error_Handler();
		}

	/** Initializes the CPU, AHB and APB buses clocks
	 */
	RCC_ClkInitStruct.ClockType = RCC_CLOCKTYPE_HCLK | RCC_CLOCKTYPE_SYSCLK | RCC_CLOCKTYPE_PCLK1 | RCC_CLOCKTYPE_PCLK2 | RCC_CLOCKTYPE_PCLK3;
	RCC_ClkInitStruct.SYSCLKSource = RCC_SYSCLKSOURCE_HSI;
	RCC_ClkInitStruct.AHBCLKDivider = RCC_SYSCLK_DIV1;
	RCC_ClkInitStruct.APB1CLKDivider = RCC_HCLK_DIV1;
	RCC_ClkInitStruct.APB2CLKDivider = RCC_HCLK_DIV1;
	RCC_ClkInitStruct.APB3CLKDivider = RCC_HCLK_DIV1;

	if(HAL_RCC_ClockConfig(&RCC_ClkInitStruct, FLASH_LATENCY_3) != HAL_OK)
		{
			Error_Handler();
		}

	/** Configure the programming delay
	 */
	__HAL_FLASH_SET_PROGRAM_DELAY(FLASH_PROGRAMMING_DELAY_1);
}

void PeriphCommonClock_Config(void)
{
	RCC_PeriphCLKInitTypeDef PeriphClkInitStruct =
		{0};

	/** Initializes the peripherals clock
	 */
	PeriphClkInitStruct.PeriphClockSelection = RCC_PERIPHCLK_ADCDAC | RCC_PERIPHCLK_FDCAN | RCC_PERIPHCLK_SPI1;
	PeriphClkInitStruct.PLL2.PLL2Source = RCC_PLL2_SOURCE_HSI;
	PeriphClkInitStruct.PLL2.PLL2M = 4;
	PeriphClkInitStruct.PLL2.PLL2N = 8;
	PeriphClkInitStruct.PLL2.PLL2P = 16;
	PeriphClkInitStruct.PLL2.PLL2Q = 16;
	PeriphClkInitStruct.PLL2.PLL2R = 16;
	PeriphClkInitStruct.PLL2.PLL2RGE = RCC_PLL2_VCIRANGE_3;
	PeriphClkInitStruct.PLL2.PLL2VCOSEL = RCC_PLL2_VCORANGE_WIDE;
	PeriphClkInitStruct.PLL2.PLL2FRACN = 0;
	PeriphClkInitStruct.PLL2.PLL2ClockOut = RCC_PLL2_DIVP | RCC_PLL2_DIVQ | RCC_PLL2_DIVR;
	PeriphClkInitStruct.FdcanClockSelection = RCC_FDCANCLKSOURCE_PLL2Q;
	PeriphClkInitStruct.AdcDacClockSelection = RCC_ADCDACCLKSOURCE_PLL2R;
	PeriphClkInitStruct.Spi1ClockSelection = RCC_SPI1CLKSOURCE_PLL2P;
	if(HAL_RCCEx_PeriphCLKConfig(&PeriphClkInitStruct) != HAL_OK)
		{
			Error_Handler();
		}
}

static void MX_ADC1_Init(void)
{

	ADC_ChannelConfTypeDef sConfig =
		{0};

	/** Common config
	 */
	hadc1.Instance = ADC1;
	hadc1.Init.ClockPrescaler = ADC_CLOCK_ASYNC_DIV1;
	hadc1.Init.Resolution = ADC_RESOLUTION_12B;
	hadc1.Init.DataAlign = ADC_DATAALIGN_RIGHT;
	hadc1.Init.ScanConvMode = ADC_SCAN_ENABLE;
	hadc1.Init.EOCSelection = ADC_EOC_SINGLE_CONV;
	hadc1.Init.LowPowerAutoWait = DISABLE;
	hadc1.Init.ContinuousConvMode = DISABLE;
	hadc1.Init.NbrOfConversion = 4;
	hadc1.Init.DiscontinuousConvMode = DISABLE;
	hadc1.Init.ExternalTrigConv = ADC_EXTERNALTRIG_T1_TRGO;
	hadc1.Init.ExternalTrigConvEdge = ADC_EXTERNALTRIGCONVEDGE_RISING;
	hadc1.Init.DMAContinuousRequests = ENABLE;
	hadc1.Init.SamplingMode = ADC_SAMPLING_MODE_NORMAL;
	hadc1.Init.Overrun = ADC_OVR_DATA_OVERWRITTEN;
	hadc1.Init.OversamplingMode = DISABLE;
	if(HAL_ADC_Init(&hadc1) != HAL_OK)
		{
			Error_Handler();
		}

	/** Configure Regular Channel
	 */
	sConfig.Channel = ADC_CHANNEL_0;
	sConfig.Rank = ADC_REGULAR_RANK_1;
	sConfig.SamplingTime = ADC_SAMPLETIME_640CYCLES_5;
	sConfig.SingleDiff = ADC_SINGLE_ENDED;
	sConfig.OffsetNumber = ADC_OFFSET_NONE;
	sConfig.Offset = 0;
	if(HAL_ADC_ConfigChannel(&hadc1, &sConfig) != HAL_OK)
		{
			Error_Handler();
		}

	/** Configure Regular Channel
	 */
	sConfig.Channel = ADC_CHANNEL_VBAT;
	sConfig.Rank = ADC_REGULAR_RANK_2;
	if(HAL_ADC_ConfigChannel(&hadc1, &sConfig) != HAL_OK)
		{
			Error_Handler();
		}

	/** Configure Regular Channel
	 */
	sConfig.Channel = ADC_CHANNEL_TEMPSENSOR;
	sConfig.Rank = ADC_REGULAR_RANK_3;
	if(HAL_ADC_ConfigChannel(&hadc1, &sConfig) != HAL_OK)
		{
			Error_Handler();
		}

	/** Configure Regular Channel
	 */
	sConfig.Channel = ADC_CHANNEL_VREFINT;
	sConfig.Rank = ADC_REGULAR_RANK_4;
	if(HAL_ADC_ConfigChannel(&hadc1, &sConfig) != HAL_OK)
		{
			Error_Handler();
		}
	/* USER CODE BEGIN ADC1_Init 2 */
	HAL_ADCEx_Calibration_Start(&hadc1, ADC_SINGLE_ENDED);
	/* USER CODE END ADC1_Init 2 */

}

static void MX_FDCAN1_Init(void)
{

	hfdcan1.Instance = FDCAN1;
	hfdcan1.Init.ClockDivider = FDCAN_CLOCK_DIV1;
	hfdcan1.Init.FrameFormat = FDCAN_FRAME_CLASSIC;
	hfdcan1.Init.Mode = FDCAN_MODE_NORMAL;
	hfdcan1.Init.AutoRetransmission = DISABLE;
	hfdcan1.Init.TransmitPause = DISABLE;
	hfdcan1.Init.ProtocolException = DISABLE;
	hfdcan1.Init.NominalPrescaler = 16;
	hfdcan1.Init.NominalSyncJumpWidth = 1;
	hfdcan1.Init.NominalTimeSeg1 = 1;
	hfdcan1.Init.NominalTimeSeg2 = 1;
	hfdcan1.Init.DataPrescaler = 1;
	hfdcan1.Init.DataSyncJumpWidth = 1;
	hfdcan1.Init.DataTimeSeg1 = 1;
	hfdcan1.Init.DataTimeSeg2 = 1;
	hfdcan1.Init.StdFiltersNbr = 0;
	hfdcan1.Init.ExtFiltersNbr = 0;
	hfdcan1.Init.TxFifoQueueMode = FDCAN_TX_FIFO_OPERATION;
	if(HAL_FDCAN_Init(&hfdcan1) != HAL_OK)
		{
			Error_Handler();
		}

}

static void MX_GPDMA1_Init(void)
{

	/* Peripheral clock enable */
	__HAL_RCC_GPDMA1_CLK_ENABLE();

	/* GPDMA1 interrupt Init */
	HAL_NVIC_SetPriority(GPDMA1_Channel0_IRQn, 0, 0);
	HAL_NVIC_EnableIRQ(GPDMA1_Channel0_IRQn);
	HAL_NVIC_SetPriority(GPDMA1_Channel1_IRQn, 0, 0);
	HAL_NVIC_EnableIRQ(GPDMA1_Channel1_IRQn);
	HAL_NVIC_SetPriority(GPDMA1_Channel3_IRQn, 0, 0);
	HAL_NVIC_EnableIRQ(GPDMA1_Channel3_IRQn);
	HAL_NVIC_SetPriority(GPDMA1_Channel5_IRQn, 0, 0);
	HAL_NVIC_EnableIRQ(GPDMA1_Channel5_IRQn);
	HAL_NVIC_SetPriority(GPDMA1_Channel6_IRQn, 0, 0);
	HAL_NVIC_EnableIRQ(GPDMA1_Channel6_IRQn);
	HAL_NVIC_SetPriority(GPDMA1_Channel7_IRQn, 0, 0);
	HAL_NVIC_EnableIRQ(GPDMA1_Channel7_IRQn);

	handle_GPDMA1_Channel7.Instance = GPDMA1_Channel7;
	handle_GPDMA1_Channel7.InitLinkedList.Priority = DMA_LOW_PRIORITY_HIGH_WEIGHT;
	handle_GPDMA1_Channel7.InitLinkedList.LinkStepMode = DMA_LSM_FULL_EXECUTION;
	handle_GPDMA1_Channel7.InitLinkedList.LinkAllocatedPort = DMA_LINK_ALLOCATED_PORT1;
	handle_GPDMA1_Channel7.InitLinkedList.TransferEventMode = DMA_TCEM_LAST_LL_ITEM_TRANSFER;
	handle_GPDMA1_Channel7.InitLinkedList.LinkedListMode = DMA_LINKEDLIST_NORMAL;
	if(HAL_DMAEx_List_Init(&handle_GPDMA1_Channel7) != HAL_OK)
		{
			Error_Handler();
		}
	if(HAL_DMA_ConfigChannelAttributes(&handle_GPDMA1_Channel7, DMA_CHANNEL_NPRIV) != HAL_OK)
		{
			Error_Handler();
		}
	handle_GPDMA1_Channel6.Instance = GPDMA1_Channel6;
	handle_GPDMA1_Channel6.InitLinkedList.Priority = DMA_LOW_PRIORITY_HIGH_WEIGHT;
	handle_GPDMA1_Channel6.InitLinkedList.LinkStepMode = DMA_LSM_FULL_EXECUTION;
	handle_GPDMA1_Channel6.InitLinkedList.LinkAllocatedPort = DMA_LINK_ALLOCATED_PORT0;
	handle_GPDMA1_Channel6.InitLinkedList.TransferEventMode = DMA_TCEM_LAST_LL_ITEM_TRANSFER;
	handle_GPDMA1_Channel6.InitLinkedList.LinkedListMode = DMA_LINKEDLIST_NORMAL;
	if(HAL_DMAEx_List_Init(&handle_GPDMA1_Channel6) != HAL_OK)
		{
			Error_Handler();
		}
	if(HAL_DMA_ConfigChannelAttributes(&handle_GPDMA1_Channel6, DMA_CHANNEL_NPRIV) != HAL_OK)
		{
			Error_Handler();
		}

}

static void MX_GPDMA2_Init(void)
{

	/* Peripheral clock enable */
	__HAL_RCC_GPDMA2_CLK_ENABLE();

	/* GPDMA2 interrupt Init */
	HAL_NVIC_SetPriority(GPDMA2_Channel0_IRQn, 0, 0);
	HAL_NVIC_EnableIRQ(GPDMA2_Channel0_IRQn);
	HAL_NVIC_SetPriority(GPDMA2_Channel1_IRQn, 0, 0);
	HAL_NVIC_EnableIRQ(GPDMA2_Channel1_IRQn);

}

static void MX_I2C2_Init(void)
{

	hi2c2.Instance = I2C2;
	hi2c2.Init.Timing = 0x10707DBC;
	hi2c2.Init.OwnAddress1 = 0;
	hi2c2.Init.AddressingMode = I2C_ADDRESSINGMODE_7BIT;
	hi2c2.Init.DualAddressMode = I2C_DUALADDRESS_DISABLE;
	hi2c2.Init.OwnAddress2 = 0;
	hi2c2.Init.OwnAddress2Masks = I2C_OA2_NOMASK;
	hi2c2.Init.GeneralCallMode = I2C_GENERALCALL_DISABLE;
	hi2c2.Init.NoStretchMode = I2C_NOSTRETCH_DISABLE;
	if(HAL_I2C_Init(&hi2c2) != HAL_OK)
		{
			Error_Handler();
		}

	/** Configure Analogue filter
	 */
	if(HAL_I2CEx_ConfigAnalogFilter(&hi2c2, I2C_ANALOGFILTER_ENABLE) != HAL_OK)
		{
			Error_Handler();
		}

	/** Configure Digital filter
	 */
	if(HAL_I2CEx_ConfigDigitalFilter(&hi2c2, 0) != HAL_OK)
		{
			Error_Handler();
		}

}

static void MX_ICACHE_Init(void)
{

	/** Enable instruction cache (default 2-ways set associative cache)
	 */
	if(HAL_ICACHE_Enable() != HAL_OK)
		{
			Error_Handler();
		}

}

static void MX_RTC_Init(void)
{

	RTC_PrivilegeStateTypeDef privilegeState =
		{0};
	RTC_TimeTypeDef sTime =
		{0};
	RTC_DateTypeDef sDate =
		{0};

	/** Initialize RTC Only
	 */
	hrtc.Instance = RTC;
	hrtc.Init.HourFormat = RTC_HOURFORMAT_24;
	hrtc.Init.AsynchPrediv = 127;
	hrtc.Init.SynchPrediv = 255;
	hrtc.Init.OutPut = RTC_OUTPUT_DISABLE;
	hrtc.Init.OutPutRemap = RTC_OUTPUT_REMAP_NONE;
	hrtc.Init.OutPutPolarity = RTC_OUTPUT_POLARITY_HIGH;
	hrtc.Init.OutPutType = RTC_OUTPUT_TYPE_OPENDRAIN;
	hrtc.Init.OutPutPullUp = RTC_OUTPUT_PULLUP_NONE;
	hrtc.Init.BinMode = RTC_BINARY_NONE;
	if(HAL_RTC_Init(&hrtc) != HAL_OK)
		{
			Error_Handler();
		}
	privilegeState.rtcPrivilegeFull = RTC_PRIVILEGE_FULL_NO;
	privilegeState.backupRegisterPrivZone = RTC_PRIVILEGE_BKUP_ZONE_NONE;
	privilegeState.backupRegisterStartZone2 = RTC_BKP_DR0;
	privilegeState.backupRegisterStartZone3 = RTC_BKP_DR0;
	if(HAL_RTCEx_PrivilegeModeSet(&hrtc, &privilegeState) != HAL_OK)
		{
			Error_Handler();
		}

	/** Initialize RTC and set the Time and Date
	 */
	sTime.Hours = 23;
	sTime.Minutes = 59;
	sTime.Seconds = 0;
	sTime.DayLightSaving = RTC_DAYLIGHTSAVING_NONE;
	sTime.StoreOperation = RTC_STOREOPERATION_RESET;
	if(HAL_RTC_SetTime(&hrtc, &sTime, RTC_FORMAT_BIN) != HAL_OK)
		{
			Error_Handler();
		}
	sDate.WeekDay = RTC_WEEKDAY_SATURDAY;
	sDate.Month = RTC_MONTH_JANUARY;
	sDate.Date = 5;
	sDate.Year = 80;

	if(HAL_RTC_SetDate(&hrtc, &sDate, RTC_FORMAT_BIN) != HAL_OK)
		{
			Error_Handler();
		}

}

static void MX_SPI1_Init(void)
{

	/* SPI1 parameter configuration*/
	hspi1.Instance = SPI1;
	hspi1.Init.Mode = SPI_MODE_MASTER;
	hspi1.Init.Direction = SPI_DIRECTION_2LINES;
	hspi1.Init.DataSize = SPI_DATASIZE_8BIT;
	hspi1.Init.CLKPolarity = SPI_POLARITY_HIGH;
	hspi1.Init.CLKPhase = SPI_PHASE_2EDGE;
	hspi1.Init.NSS = SPI_NSS_SOFT;
	hspi1.Init.BaudRatePrescaler = SPI_BAUDRATEPRESCALER_2;
	hspi1.Init.FirstBit = SPI_FIRSTBIT_MSB;
	hspi1.Init.TIMode = SPI_TIMODE_DISABLE;
	hspi1.Init.CRCCalculation = SPI_CRCCALCULATION_DISABLE;
	hspi1.Init.CRCPolynomial = 0x7;
	hspi1.Init.NSSPMode = SPI_NSS_PULSE_DISABLE;
	hspi1.Init.NSSPolarity = SPI_NSS_POLARITY_LOW;
	hspi1.Init.FifoThreshold = SPI_FIFO_THRESHOLD_01DATA;
	hspi1.Init.MasterSSIdleness = SPI_MASTER_SS_IDLENESS_00CYCLE;
	hspi1.Init.MasterInterDataIdleness = SPI_MASTER_INTERDATA_IDLENESS_00CYCLE;
	hspi1.Init.MasterReceiverAutoSusp = SPI_MASTER_RX_AUTOSUSP_DISABLE;
	hspi1.Init.MasterKeepIOState = SPI_MASTER_KEEP_IO_STATE_DISABLE;
	hspi1.Init.IOSwap = SPI_IO_SWAP_DISABLE;
	hspi1.Init.ReadyMasterManagement = SPI_RDY_MASTER_MANAGEMENT_INTERNALLY;
	hspi1.Init.ReadyPolarity = SPI_RDY_POLARITY_HIGH;
	if(HAL_SPI_Init(&hspi1) != HAL_OK)
		{
			Error_Handler();
		}

}

static void MX_TIM1_Init(void)
{

	TIM_ClockConfigTypeDef sClockSourceConfig =
		{0};
	TIM_MasterConfigTypeDef sMasterConfig =
		{0};

	htim1.Instance = TIM1;
	htim1.Init.Prescaler = 639;
	htim1.Init.CounterMode = TIM_COUNTERMODE_UP;
	htim1.Init.Period = 6260;
	htim1.Init.ClockDivision = TIM_CLOCKDIVISION_DIV1;
	htim1.Init.RepetitionCounter = 0;
	htim1.Init.AutoReloadPreload = TIM_AUTORELOAD_PRELOAD_DISABLE;
	if(HAL_TIM_Base_Init(&htim1) != HAL_OK)
		{
			Error_Handler();
		}
	sClockSourceConfig.ClockSource = TIM_CLOCKSOURCE_INTERNAL;
	if(HAL_TIM_ConfigClockSource(&htim1, &sClockSourceConfig) != HAL_OK)
		{
			Error_Handler();
		}
	sMasterConfig.MasterOutputTrigger = TIM_TRGO_UPDATE;
	sMasterConfig.MasterOutputTrigger2 = TIM_TRGO2_RESET;
	sMasterConfig.MasterSlaveMode = TIM_MASTERSLAVEMODE_DISABLE;
	if(HAL_TIMEx_MasterConfigSynchronization(&htim1, &sMasterConfig) != HAL_OK)
		{
			Error_Handler();
		}

}

static void MX_TIM2_Init(void)
{

	TIM_Encoder_InitTypeDef sConfig =
		{0};
	TIM_MasterConfigTypeDef sMasterConfig =
		{0};

	htim2.Instance = TIM2;
	htim2.Init.Prescaler = 0;
	htim2.Init.CounterMode = TIM_COUNTERMODE_UP;
	htim2.Init.Period = 4294967295;
	htim2.Init.ClockDivision = TIM_CLOCKDIVISION_DIV1;
	htim2.Init.AutoReloadPreload = TIM_AUTORELOAD_PRELOAD_DISABLE;
	sConfig.EncoderMode = TIM_ENCODERMODE_TI1;
	sConfig.IC1Polarity = TIM_ICPOLARITY_RISING;
	sConfig.IC1Selection = TIM_ICSELECTION_DIRECTTI;
	sConfig.IC1Prescaler = TIM_ICPSC_DIV1;
	sConfig.IC1Filter = 0;
	sConfig.IC2Polarity = TIM_ICPOLARITY_RISING;
	sConfig.IC2Selection = TIM_ICSELECTION_DIRECTTI;
	sConfig.IC2Prescaler = TIM_ICPSC_DIV1;
	sConfig.IC2Filter = 0;
	if(HAL_TIM_Encoder_Init(&htim2, &sConfig) != HAL_OK)
		{
			Error_Handler();
		}
	sMasterConfig.MasterOutputTrigger = TIM_TRGO_RESET;
	sMasterConfig.MasterSlaveMode = TIM_MASTERSLAVEMODE_DISABLE;
	if(HAL_TIMEx_MasterConfigSynchronization(&htim2, &sMasterConfig) != HAL_OK)
		{
			Error_Handler();
		}

}

static void MX_USART1_UART_Init(void)
{

	huart1.Instance = USART1;
	huart1.Init.BaudRate = 9600;
	huart1.Init.WordLength = UART_WORDLENGTH_8B;
	huart1.Init.StopBits = UART_STOPBITS_1;
	huart1.Init.Parity = UART_PARITY_NONE;
	huart1.Init.Mode = UART_MODE_TX_RX;
	huart1.Init.HwFlowCtl = UART_HWCONTROL_NONE;
	huart1.Init.OverSampling = UART_OVERSAMPLING_16;
	huart1.Init.OneBitSampling = UART_ONE_BIT_SAMPLE_DISABLE;
	huart1.Init.ClockPrescaler = UART_PRESCALER_DIV1;
	huart1.AdvancedInit.AdvFeatureInit = UART_ADVFEATURE_NO_INIT;
	if(HAL_UART_Init(&huart1) != HAL_OK)
		{
			Error_Handler();
		}
	if(HAL_UARTEx_SetTxFifoThreshold(&huart1, UART_TXFIFO_THRESHOLD_1_8) != HAL_OK)
		{
			Error_Handler();
		}
	if(HAL_UARTEx_SetRxFifoThreshold(&huart1, UART_RXFIFO_THRESHOLD_1_8) != HAL_OK)
		{
			Error_Handler();
		}
	if(HAL_UARTEx_DisableFifoMode(&huart1) != HAL_OK)
		{
			Error_Handler();
		}

}

static void MX_USART3_UART_Init(void)
{

	huart3.Instance = USART3;
	huart3.Init.BaudRate = 115200;
	huart3.Init.WordLength = UART_WORDLENGTH_8B;
	huart3.Init.StopBits = UART_STOPBITS_1;
	huart3.Init.Parity = UART_PARITY_NONE;
	huart3.Init.Mode = UART_MODE_TX_RX;
	huart3.Init.HwFlowCtl = UART_HWCONTROL_NONE;
	huart3.Init.OverSampling = UART_OVERSAMPLING_16;
	huart3.Init.OneBitSampling = UART_ONE_BIT_SAMPLE_DISABLE;
	huart3.Init.ClockPrescaler = UART_PRESCALER_DIV1;
	huart3.AdvancedInit.AdvFeatureInit = UART_ADVFEATURE_NO_INIT;
	if(HAL_UART_Init(&huart3) != HAL_OK)
		{
			Error_Handler();
		}
	if(HAL_UARTEx_SetTxFifoThreshold(&huart3, UART_TXFIFO_THRESHOLD_1_8) != HAL_OK)
		{
			Error_Handler();
		}
	if(HAL_UARTEx_SetRxFifoThreshold(&huart3, UART_RXFIFO_THRESHOLD_1_8) != HAL_OK)
		{
			Error_Handler();
		}
	if(HAL_UARTEx_DisableFifoMode(&huart3) != HAL_OK)
		{
			Error_Handler();
		}

}

static void MX_USB_PCD_Init(void)
{

	hpcd_USB_DRD_FS.Instance = USB_DRD_FS;
	hpcd_USB_DRD_FS.Init.dev_endpoints = 8;
	hpcd_USB_DRD_FS.Init.speed = USBD_FS_SPEED;
	hpcd_USB_DRD_FS.Init.phy_itface = PCD_PHY_EMBEDDED;
	hpcd_USB_DRD_FS.Init.Sof_enable = DISABLE;
	hpcd_USB_DRD_FS.Init.low_power_enable = DISABLE;
	hpcd_USB_DRD_FS.Init.lpm_enable = DISABLE;
	hpcd_USB_DRD_FS.Init.battery_charging_enable = DISABLE;
	hpcd_USB_DRD_FS.Init.vbus_sensing_enable = DISABLE;
	hpcd_USB_DRD_FS.Init.bulk_doublebuffer_enable = DISABLE;
	hpcd_USB_DRD_FS.Init.iso_singlebuffer_enable = DISABLE;
	if(HAL_PCD_Init(&hpcd_USB_DRD_FS) != HAL_OK)
		{
			Error_Handler();
		}

}

static void MX_GPIO_Init(void)
{
	GPIO_InitTypeDef GPIO_InitStruct =
		{0};

	/* GPIO Ports Clock Enable */
	__HAL_RCC_GPIOC_CLK_ENABLE();
	__HAL_RCC_GPIOH_CLK_ENABLE();
	__HAL_RCC_GPIOA_CLK_ENABLE();
	__HAL_RCC_GPIOB_CLK_ENABLE();
	__HAL_RCC_GPIOD_CLK_ENABLE();

	/*Configure GPIO pin Output Level */
	HAL_GPIO_WritePin(GPIOC, LED_Red_Pin | LED_Yellow_Pin | GPS_PWR_CTRL_Pin | Debug_Out_Pin | USB_FS_PWR_EN_Pin | SUPERCAP_DISCHARGE_Pin, GPIO_PIN_RESET);

	/*Configure GPIO pin Output Level */
	HAL_GPIO_WritePin(GPS_RESET_GPIO_Port, GPS_RESET_Pin, GPIO_PIN_SET);

	/*Configure GPIO pin Output Level */
	HAL_GPIO_WritePin(GPIOA, SPI1_SD_CS_Pin | SPI1_FRAM_CS_Pin, GPIO_PIN_SET);

	/*Configure GPIO pin Output Level */
	HAL_GPIO_WritePin(LED_Green_GPIO_Port, LED_Green_Pin, GPIO_PIN_RESET);

	/*Configure GPIO pin Output Level */
	HAL_GPIO_WritePin(GPIOB, CAN_STBY_Pin | SUPERCAP_EN_Pin, GPIO_PIN_RESET);

	/*Configure GPIO pin Output Level */
	HAL_GPIO_WritePin(GPIOB, SPI1_ADXL345_CS_Pin | Anal_SW_CTRL_Pin, GPIO_PIN_SET);

	/*Configure GPIO pins : Blue_User_Button_Pin ADXL345_INT1_Pin */
	GPIO_InitStruct.Pin = Blue_User_Button_Pin | ADXL345_INT1_Pin;
	GPIO_InitStruct.Mode = GPIO_MODE_IT_RISING;
	GPIO_InitStruct.Pull = GPIO_NOPULL;
	HAL_GPIO_Init(GPIOC, &GPIO_InitStruct);

	/*Configure GPIO pins : LED_Red_Pin LED_Yellow_Pin USB_FS_PWR_EN_Pin */
	GPIO_InitStruct.Pin = LED_Red_Pin | LED_Yellow_Pin | USB_FS_PWR_EN_Pin;
	GPIO_InitStruct.Mode = GPIO_MODE_OUTPUT_PP;
	GPIO_InitStruct.Pull = GPIO_NOPULL;
	GPIO_InitStruct.Speed = GPIO_SPEED_FREQ_LOW;
	HAL_GPIO_Init(GPIOC, &GPIO_InitStruct);

	/*Configure GPIO pin : GPS_WKUP_Pin */
	GPIO_InitStruct.Pin = GPS_WKUP_Pin;
	GPIO_InitStruct.Mode = GPIO_MODE_INPUT;
	GPIO_InitStruct.Pull = GPIO_PULLDOWN;
	HAL_GPIO_Init(GPS_WKUP_GPIO_Port, &GPIO_InitStruct);

	/*Configure GPIO pin : GPS_RESET_Pin */
	GPIO_InitStruct.Pin = GPS_RESET_Pin;
	GPIO_InitStruct.Mode = GPIO_MODE_OUTPUT_PP;
	GPIO_InitStruct.Pull = GPIO_PULLUP;
	GPIO_InitStruct.Speed = GPIO_SPEED_FREQ_LOW;
	HAL_GPIO_Init(GPS_RESET_GPIO_Port, &GPIO_InitStruct);

	/*Configure GPIO pins : SPI1_SD_CS_Pin SPI1_FRAM_CS_Pin */
	GPIO_InitStruct.Pin = SPI1_SD_CS_Pin | SPI1_FRAM_CS_Pin;
	GPIO_InitStruct.Mode = GPIO_MODE_OUTPUT_PP;
	GPIO_InitStruct.Pull = GPIO_PULLUP;
	GPIO_InitStruct.Speed = GPIO_SPEED_FREQ_LOW;
	HAL_GPIO_Init(GPIOA, &GPIO_InitStruct);

	/*Configure GPIO pin : LED_Green_Pin */
	GPIO_InitStruct.Pin = LED_Green_Pin;
	GPIO_InitStruct.Mode = GPIO_MODE_OUTPUT_PP;
	GPIO_InitStruct.Pull = GPIO_NOPULL;
	GPIO_InitStruct.Speed = GPIO_SPEED_FREQ_LOW;
	HAL_GPIO_Init(LED_Green_GPIO_Port, &GPIO_InitStruct);

	/*Configure GPIO pins : PA7 PA10 */
	GPIO_InitStruct.Pin = GPIO_PIN_7 | GPIO_PIN_10;
	GPIO_InitStruct.Mode = GPIO_MODE_ANALOG;
	GPIO_InitStruct.Pull = GPIO_NOPULL;
	HAL_GPIO_Init(GPIOA, &GPIO_InitStruct);

	/*Configure GPIO pins : GPS_PWR_CTRL_Pin SUPERCAP_DISCHARGE_Pin */
	GPIO_InitStruct.Pin = GPS_PWR_CTRL_Pin | SUPERCAP_DISCHARGE_Pin;
	GPIO_InitStruct.Mode = GPIO_MODE_OUTPUT_PP;
	GPIO_InitStruct.Pull = GPIO_PULLDOWN;
	GPIO_InitStruct.Speed = GPIO_SPEED_FREQ_LOW;
	HAL_GPIO_Init(GPIOC, &GPIO_InitStruct);

	/*Configure GPIO pin : PC5 */
	GPIO_InitStruct.Pin = GPIO_PIN_5;
	GPIO_InitStruct.Mode = GPIO_MODE_ANALOG;
	GPIO_InitStruct.Pull = GPIO_NOPULL;
	HAL_GPIO_Init(GPIOC, &GPIO_InitStruct);

	/*Configure GPIO pins : PB0 PB1 */
	GPIO_InitStruct.Pin = GPIO_PIN_0 | GPIO_PIN_1;
	GPIO_InitStruct.Mode = GPIO_MODE_ANALOG;
	GPIO_InitStruct.Pull = GPIO_NOPULL;
	HAL_GPIO_Init(GPIOB, &GPIO_InitStruct);

	/*Configure GPIO pin : CAN_STBY_Pin */
	GPIO_InitStruct.Pin = CAN_STBY_Pin;
	GPIO_InitStruct.Mode = GPIO_MODE_OUTPUT_PP;
	GPIO_InitStruct.Pull = GPIO_NOPULL;
	GPIO_InitStruct.Speed = GPIO_SPEED_FREQ_LOW;
	HAL_GPIO_Init(CAN_STBY_GPIO_Port, &GPIO_InitStruct);

	/*Configure GPIO pin : Debug_Out_Pin */
	GPIO_InitStruct.Pin = Debug_Out_Pin;
	GPIO_InitStruct.Mode = GPIO_MODE_OUTPUT_PP;
	GPIO_InitStruct.Pull = GPIO_NOPULL;
	GPIO_InitStruct.Speed = GPIO_SPEED_FREQ_VERY_HIGH;
	HAL_GPIO_Init(Debug_Out_GPIO_Port, &GPIO_InitStruct);

	/*Configure GPIO pin : USB_FS_VBUS_Pin */
	GPIO_InitStruct.Pin = USB_FS_VBUS_Pin;
	GPIO_InitStruct.Mode = GPIO_MODE_INPUT;
	GPIO_InitStruct.Pull = GPIO_NOPULL;
	HAL_GPIO_Init(USB_FS_VBUS_GPIO_Port, &GPIO_InitStruct);

	/*Configure GPIO pin : SD_CD_Pin */
	GPIO_InitStruct.Pin = SD_CD_Pin;
	GPIO_InitStruct.Mode = GPIO_MODE_INPUT;
	GPIO_InitStruct.Pull = GPIO_PULLUP;
	HAL_GPIO_Init(SD_CD_GPIO_Port, &GPIO_InitStruct);

	/*Configure GPIO pin : USB_FS_OVCR_Pin */
	GPIO_InitStruct.Pin = USB_FS_OVCR_Pin;
	GPIO_InitStruct.Mode = GPIO_MODE_IT_RISING;
	GPIO_InitStruct.Pull = GPIO_NOPULL;
	HAL_GPIO_Init(USB_FS_OVCR_GPIO_Port, &GPIO_InitStruct);

	/*Configure GPIO pins : SPI1_ADXL345_CS_Pin Anal_SW_CTRL_Pin */
	GPIO_InitStruct.Pin = SPI1_ADXL345_CS_Pin | Anal_SW_CTRL_Pin;
	GPIO_InitStruct.Mode = GPIO_MODE_OUTPUT_PP;
	GPIO_InitStruct.Pull = GPIO_PULLUP;
	GPIO_InitStruct.Speed = GPIO_SPEED_FREQ_LOW;
	HAL_GPIO_Init(GPIOB, &GPIO_InitStruct);

	/*Configure GPIO pin : SUPERCAP_EN_Pin */
	GPIO_InitStruct.Pin = SUPERCAP_EN_Pin;
	GPIO_InitStruct.Mode = GPIO_MODE_OUTPUT_PP;
	GPIO_InitStruct.Pull = GPIO_PULLDOWN;
	GPIO_InitStruct.Speed = GPIO_SPEED_FREQ_LOW;
	HAL_GPIO_Init(SUPERCAP_EN_GPIO_Port, &GPIO_InitStruct);

	/* EXTI interrupt init*/
	HAL_NVIC_SetPriority(EXTI2_IRQn, 0, 0);
	HAL_NVIC_EnableIRQ(EXTI2_IRQn);

	HAL_NVIC_SetPriority(EXTI9_IRQn, 1, 0);
	HAL_NVIC_EnableIRQ(EXTI9_IRQn);

	HAL_NVIC_SetPriority(EXTI13_IRQn, 4, 0);
	HAL_NVIC_EnableIRQ(EXTI13_IRQn);

	/* USER CODE BEGIN MX_GPIO_Init_2 */
	HAL_NVIC_DisableIRQ(EXTI9_IRQn);	// disable until accelerometer initialization is complete - see adxl345_ctor()
	/* USER CODE END MX_GPIO_Init_2 */
}

/* USER CODE BEGIN 4 */

// EXTI rising edge callback
void HAL_GPIO_EXTI_Rising_Callback(uint16_t GPIO_Pin)
{
	if(GPIO_Pin == Blue_User_Button_Pin)  // if button is pressed
		{
			HAL_GPIO_TogglePin(LED_Red_GPIO_Port, LED_Red_Pin);
			return;
		}

#if USE_ADXL345
	if(GPIO_Pin == ADXL345_INT1_Pin)  // accelerometer interrupt (act. or inact.)
		{
			ADXL345->ISR();  // execute the ISR callback
			return;
		}
#endif
}

// EXTI falling edge callback
void HAL_GPIO_EXTI_Falling_Callback(uint16_t GPIO_Pin)
{
	if(GPIO_Pin == SD_CD_Pin)  // if card is removed
		{
			;  // TODO - SD card detect irq - implement disable read/write operations
			// TODO - SD card detect irq - also make sure that before any read/write, this GPIO state is checked
		}
}

// UART complete reception
void HAL_UART_RxCpltCallback(UART_HandleTypeDef *huart)
{
	if(huart == &huart1)
		{
			;
		}

	if(huart == &huart3)
		{
			;
		}
}

// UART RX events - RX Half-Complete/Complete & idle line interrupts
void HAL_UARTEx_RxEventCallback(UART_HandleTypeDef *huart, uint16_t Size)
{
	if(huart == &huart1)
		{
			ORG1510MK4->Parse(Size);
		}

	if(huart == &huart3)
		{
			load_into_ring_buffer(&uart3_sys_rx_rb, Size);  // buffer incoming UART stream into ring buffer

			lwrb_sz_t bytes_in_rb = lwrb_get_full(&uart3_sys_rx_rb);

			if(bytes_in_rb)
				{
					char c = 0;
					lwrb_peek(&uart3_sys_rx_rb, bytes_in_rb - 1, &c, 1);

					if(c == '\r')
						{
							lwrb_read(&uart3_sys_rx_rb, SYS_out, bytes_in_rb);
							uint8_t len = (uint8_t) strlen((const char*) SYS_out);
							SYS_out[len - 1] = '\0';

							if(!(SYS_out[0] >= 'A' && SYS_out[0] <= 'Z'))  // crude filter against non-printable characeters in input
								{
									memset(SYS_out, '\0', 82);  // zero out out-container
									return;
								}

							ORG1510MK4->Write((const char*) SYS_out);
							memset(SYS_out, '\0', 82);  // zero out out-container
							return;
						}

					lwrb_peek(&uart3_sys_rx_rb, bytes_in_rb - 2, &c, 1);
					if(c == '\e')  // ALT and some key below...
						{
							lwrb_peek(&uart3_sys_rx_rb, bytes_in_rb - 1, &c, 1);

							switch(c)
								{
								case '0':  // ALT + 0
									ORG1510MK4->Power(off);
									break;

								case '1':  // ALT + 1
									ORG1510MK4->Power(on);
									break;

								case '2':
									ORG1510MK4->Power(backup);
									break;

								case '3':
									ORG1510MK4->Power(wakeup);
									break;

								case '4':
									ORG1510MK4->Power(standby);
									break;

								case '5':
									ORG1510MK4->Power(periodic);
									break;

								case '6':
									ORG1510MK4->Power(alwayslocate);
									break;

								case '7':
									ORG1510MK4->Power(reset);
									break;

								case '8':
									ORG1510MK4->Power(discharge);
									break;

								case 'r':
									ORG1510MK4->Power(off);
									NVIC_SystemReset();
									break;

								case 'q':
									TimeHelper->LocationHelper(1);	// force location seed
									break;

								default:
									return;
								}
						}
				}
		}
}
/* USER CODE END 4 */

/* MPU Configuration */

void MPU_Config(void)
{
	MPU_Region_InitTypeDef MPU_InitStruct =
		{0};
	MPU_Attributes_InitTypeDef MPU_AttributesInit =
		{0};

	/* Disables the MPU */
	HAL_MPU_Disable();

	/** Initializes and configures the Region and the memory to be protected
	 */
	MPU_InitStruct.Enable = MPU_REGION_ENABLE;
	MPU_InitStruct.Number = MPU_REGION_NUMBER0;
	MPU_InitStruct.BaseAddress = 0x08FFF810;
	MPU_InitStruct.LimitAddress = 0x08FFF819;
	MPU_InitStruct.AttributesIndex = MPU_ATTRIBUTES_NUMBER0;
	MPU_InitStruct.AccessPermission = MPU_REGION_ALL_RO;
	MPU_InitStruct.DisableExec = MPU_INSTRUCTION_ACCESS_DISABLE;
	MPU_InitStruct.IsShareable = MPU_ACCESS_NOT_SHAREABLE;

	HAL_MPU_ConfigRegion(&MPU_InitStruct);
	MPU_AttributesInit.Number = MPU_REGION_NUMBER0;
	MPU_AttributesInit.Attributes = MPU_DEVICE_nGnRnE | MPU_WRITE_THROUGH | MPU_TRANSIENT | MPU_NO_ALLOCATE;

	HAL_MPU_ConfigMemoryAttributes(&MPU_AttributesInit);
	/* Enables the MPU */
	HAL_MPU_Enable(MPU_HFNMI_PRIVDEF);

}

void Error_Handler(void)
{
	__disable_irq();
	while(1)
		{
		}
}
